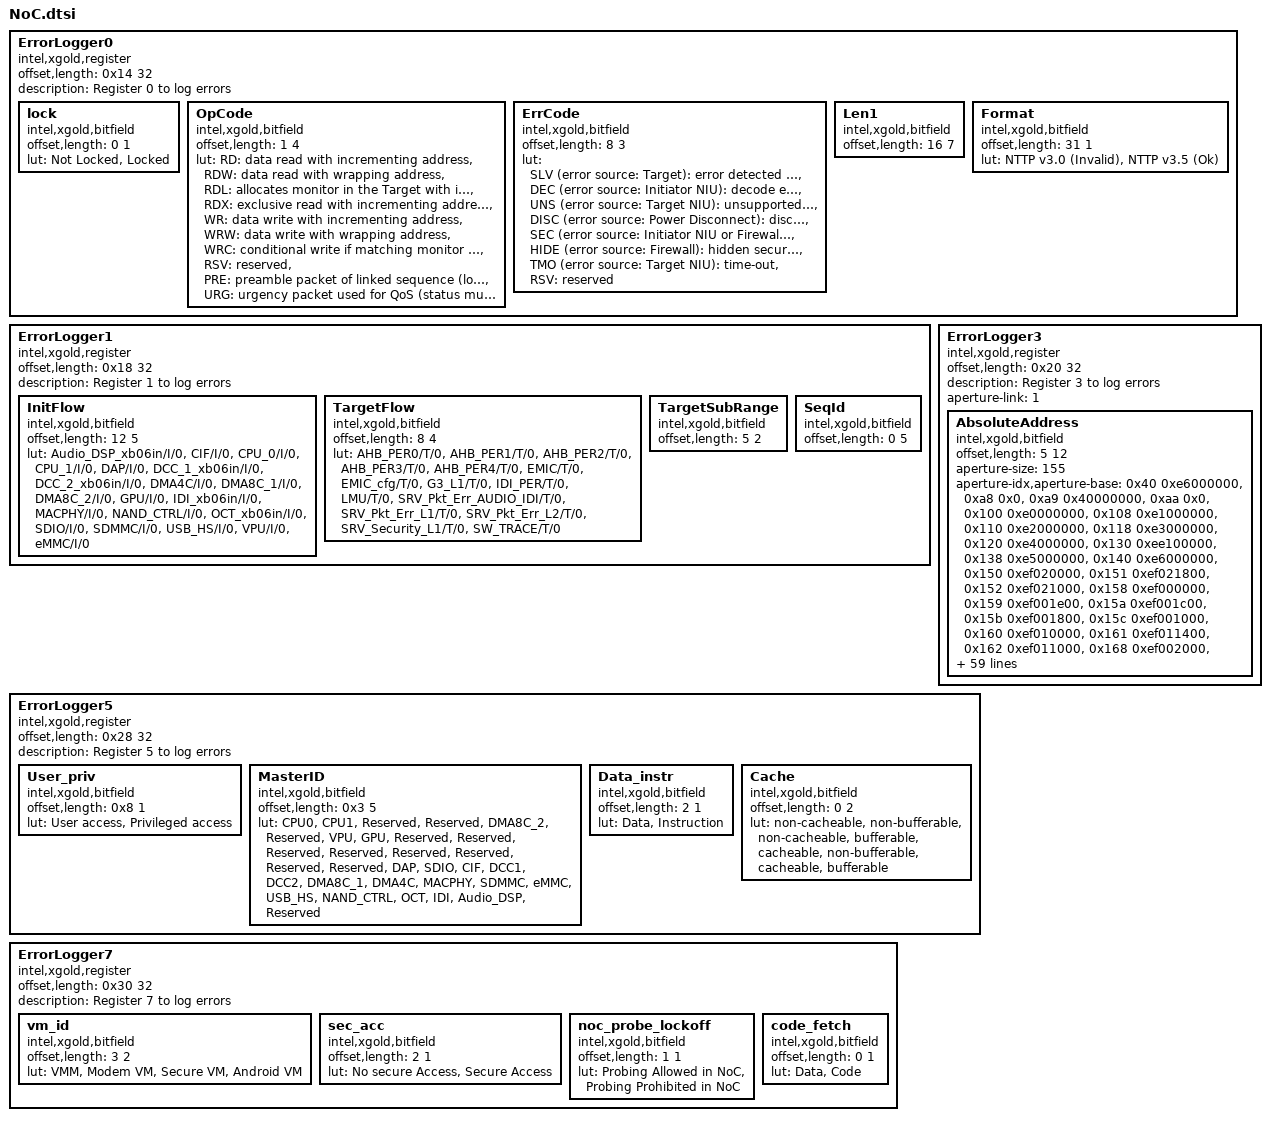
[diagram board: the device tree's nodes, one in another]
ErrorLogger0 {
	compatible = "intel,xgold,register";
	offset,length = < 0x14 32>;
	description = "Register 0 to log errors";
	lock {
		compatible = "intel,xgold,bitfield";
		offset,length = < 0 1>;
		lut = "Not Locked", "Locked";
	};
	OpCode {
		compatible = "intel,xgold,bitfield";
		offset,length = < 1 4>;
		lut = "RD: data read with incrementing address",
			"RDW: data read with wrapping address",
			"RDL: allocates monitor in the Target with incrementing address",
			"RDX: exclusive read with incrementing address",
			"WR: data write with incrementing address",
			"WRW: data write with wrapping address",
			"WRC: conditional write if matching monitor in Target is found",
			"RSV: reserved",
			"PRE: preamble packet of linked sequence (locked sequence)",
			"URG: urgency packet used for QoS (status must be REQ)";
	};
	ErrCode {
		compatible = "intel,xgold,bitfield";
		offset,length = < 8 3 >;
		lut = "SLV (error source: Target): error detected by the Slave without any information or no Error",
			"DEC (error source: Initiator NIU): decode error",
			"UNS (error source: Target NIU): unsupported access type",
			"DISC (error source: Power Disconnect): disconnected Target or NoC domain",
			"SEC (error source: Initiator NIU or Firewall): security error",
			"HIDE (error source: Firewall): hidden security error. Will be reported as OK to the initiator",
			"TMO (error source: Target NIU): time-out",
			"RSV: reserved";

	};
	Len1 {
		compatible = "intel,xgold,bitfield";
		offset,length = < 16 7 >;
	};
	Format {
		compatible = "intel,xgold,bitfield";
		offset,length = < 31 1 >;
		lut = "NTTP v3.0 (Invalid)", "NTTP v3.5 (Ok)";
	};
};

ErrorLogger1 {
	compatible = "intel,xgold,register", "intel,xgold,noc,filter,routeid";
	offset,length = < 0x18 32>;
	description = "Register 1 to log errors";
	InitFlow {
		compatible = "intel,xgold,bitfield";
		offset,length = < 12 5 >;
		lut = "Audio_DSP_xb06in/I/0",
			"CIF/I/0",
			"CPU_0/I/0",
			"CPU_1/I/0",
			"DAP/I/0",
			"DCC_1_xb06in/I/0",
			"DCC_2_xb06in/I/0",
			"DMA4C/I/0",
			"DMA8C_1/I/0",
			"DMA8C_2/I/0",
			"GPU/I/0",
			"IDI_xb06in/I/0",
			"MACPHY/I/0",
			"NAND_CTRL/I/0",
			"OCT_xb06in/I/0",
			"SDIO/I/0",
			"SDMMC/I/0",
			"USB_HS/I/0",
			"VPU/I/0",
			"eMMC/I/0";
	};

	TargetFlow {
		compatible = "intel,xgold,bitfield";
		offset,length = < 8 4 >;
		lut = "AHB_PER0/T/0",
			"AHB_PER1/T/0",
			"AHB_PER2/T/0",
			"AHB_PER3/T/0",
			"AHB_PER4/T/0",
			"EMIC/T/0",
			"EMIC_cfg/T/0",
			"G3_L1/T/0",
			"IDI_PER/T/0",
			"LMU/T/0",
			"SRV_Pkt_Err_AUDIO_IDI/T/0",
			"SRV_Pkt_Err_L1/T/0",
			"SRV_Pkt_Err_L2/T/0",
			"SRV_Security_L1/T/0",
			"SW_TRACE/T/0";
	};

	TargetSubRange {
		compatible = "intel,xgold,bitfield";
		offset,length = < 5 2 >;
	};

	SeqId {
		compatible = "intel,xgold,bitfield";
		offset,length = < 0 5 >;
	};
};

ErrorLogger3 {
	/* This register does not really include a bitfield or its bitfield is 32 bits and it provides an offset address */
	/* To calculate the absolute address, you must use the initflow:targetflow:subrange from ErrorLogger3 register */
	/* And use it as an index in the aperture table. Then you must add the value of this register to the value given */
	/* by the table to get the absolute address. */
	compatible = "intel,xgold,register";
	offset,length = < 0x20 32>;
	description = "Register 3 to log errors";
	aperture-link = <1>; /* link to ErrorLogger1 whose information are required to calculate real absolute address */
	AbsoluteAddress {
		compatible = "intel,xgold,bitfield";
		offset,length = < 5 12 >;				/* bitfield initflow:targeflow:subrange from aperture-link register */
		aperture-size= < 155 >;					/* Number of line in the aperture table below */
		aperture-idx,aperture-base =			/* Aperture_idx is concatenation of initflow:targetflow:subrange bitfield from ErrorLogger1 */
			<0x40	0xe6000000>,
			<0xa8	0x0>,
			<0xa9	0x40000000>,
			<0xaa	0x0>,
			<0x100	0xe0000000>,
			<0x108	0xe1000000>,
			<0x110	0xe2000000>,
			<0x118	0xe3000000>,
			<0x120	0xe4000000>,
			<0x130	0xee100000>,
			<0x138	0xe5000000>,
			<0x140	0xe6000000>,
			<0x150	0xef020000>,
			<0x151	0xef021800>,
			<0x152	0xef021000>,
			<0x158	0xef000000>,
			<0x159	0xef001e00>,
			<0x15a	0xef001c00>,
			<0x15b	0xef001800>,
			<0x15c	0xef001000>,
			<0x160	0xef010000>,
			<0x161	0xef011400>,
			<0x162	0xef011000>,
			<0x168	0xef002000>,
			<0x169	0xef002400>,
			<0x170	0x80000000>,
			<0x1a8	0x0>,
			<0x1a9	0x40000000>,
			<0x1aa	0x0>,
			<0x1c8	0xfff30000>,
			<0x1c9	0xfff20000>,
			<0x1ca	0xfff00000>,
			<0x1cb	0xfffc0000>,
			<0x200	0xe0000000>,
			<0x208	0xe1000000>,
			<0x210	0xe2000000>,
			<0x218	0xe3000000>,
			<0x220	0xe4000000>,
			<0x228	0x0>,
			<0x229	0x40000000>,
			<0x22a	0x0>,
			<0x230	0xee100000>,
			<0x238	0xe5000000>,
			<0x240	0xe6000000>,
			<0x248	0xfff30000>,
			<0x249	0xfff20000>,
			<0x24a	0xfff00000>,
			<0x24b	0xfffc0000>,
			<0x250	0xef020000>,
			<0x251	0xef021800>,
			<0x252	0xef021000>,
			<0x258	0xef000000>,
			<0x259	0xef001e00>,
			<0x25a	0xef001c00>,
			<0x25b	0xef001800>,
			<0x25c	0xef001000>,
			<0x260	0xef010000>,
			<0x261	0xef011400>,
			<0x262	0xef011000>,
			<0x268	0xef002000>,
			<0x269	0xef002400>,
			<0x2a8	0x0>,
			<0x2a9	0x40000000>,
			<0x2aa	0x0>,
			<0x328	0x0>,
			<0x329	0x40000000>,
			<0x32a	0x0>,
			<0x390	0xe2000000>,
			<0x398	0xe3000000>,
			<0x3a8	0x0>,
			<0x3a9	0x40000000>,
			<0x3aa	0x0>,
			<0x3c8	0xfff30000>,
			<0x3c9	0xfff20000>,
			<0x3ca	0xfff00000>,
			<0x3cb	0xfffc0000>,
			<0x408	0xe1000000>,
			<0x410	0xe2000000>,
			<0x428	0x0>,
			<0x429	0x40000000>,
			<0x42a	0x0>,
			<0x448	0xfff30000>,
			<0x449	0xfff20000>,
			<0x44a	0xfff00000>,
			<0x44b	0xfffc0000>,
			<0x488	0xe1000000>,
			<0x490	0xe2000000>,
			<0x498	0xe3000000>,
			<0x4a8	0x0>,
			<0x4a9	0x40000000>,
			<0x4aa	0x0>,
			<0x4b8	0xe5000000>,
			<0x4c8	0xfff30000>,
			<0x4c9	0xfff20000>,
			<0x4ca	0xfff00000>,
			<0x4cb	0xfffc0000>,
			<0x528	0x0>,
			<0x529	0x40000000>,
			<0x52a	0x0>,
			<0x598	0xe3000000>,
			<0x5a8	0x0>,
			<0x5a9	0x40000000>,
			<0x5aa	0x0>,
			<0x5c8	0xfff30000>,
			<0x5c9	0xfff20000>,
			<0x5ca	0xfff00000>,
			<0x5cb	0xfffc0000>,
			<0x628	0x0>,
			<0x629	0x40000000>,
			<0x62a	0x0>,
			<0x648	0xfff30000>,
			<0x649	0xfff20000>,
			<0x64a	0xfff00000>,
			<0x64b	0xfffc0000>,
			<0x6a8	0x0>,
			<0x6a9	0x40000000>,
			<0x6aa	0x0>,
			<0x6c8	0xfff30000>,
			<0x6c9	0xfff20000>,
			<0x6ca	0xfff00000>,
			<0x6cb	0xfffc0000>,
			<0x728	0x0>,
			<0x729	0x40000000>,
			<0x72a	0x0>,
			<0x7a8	0x0>,
			<0x7a9	0x40000000>,
			<0x7aa	0x0>,
			<0x7c8	0xfff30000>,
			<0x7c9	0xfff20000>,
			<0x7ca	0xfff00000>,
			<0x7cb	0xfffc0000>,
			<0x828	0x0>,
			<0x829	0x40000000>,
			<0x82a	0x0>,
			<0x848	0xfff30000>,
			<0x849	0xfff20000>,
			<0x84a	0xfff00000>,
			<0x84b	0xfffc0000>,
			<0x8a8	0x0>,
			<0x8a9	0x40000000>,
			<0x8aa	0x0>,
			<0x8c8	0xfff30000>,
			<0x8c9	0xfff20000>,
			<0x8ca	0xfff00000>,
			<0x8cb	0xfffc0000>,
			<0x928	0x0>,
			<0x929	0x40000000>,
			<0x92a	0x0>,
			<0x9a8	0x0>,
			<0x9a9	0x40000000>,
			<0x9aa	0x0>,
			<0x9c8	0xfff30000>,
			<0x9c9	0xfff20000>,
			<0x9ca	0xfff00000>,
			<0x9cb	0xfffc0000>;
	};
};

ErrorLogger5 {
	compatible = "intel,xgold,register";
	offset,length = < 0x28 32>;
	description = "Register 5 to log errors";

	User_priv {
		compatible = "intel,xgold,bitfield";
		offset,length = < 0x8 1>;
		lut = "User access", "Privileged access";
	};

	MasterID {
		compatible = "intel,xgold,bitfield";
		offset,length = < 0x3 5>;
		lut = "CPU0",
			"CPU1",
			"Reserved",
			"Reserved",
			"DMA8C_2",
			"Reserved",
			"VPU",
			"GPU",
			"Reserved",
			"Reserved",
			"Reserved",
			"Reserved",
			"Reserved",
			"Reserved",
			"Reserved",
			"Reserved",
			"DAP",
			"SDIO",
			"CIF",
			"DCC1",
			"DCC2",
			"DMA8C_1",
			"DMA4C",
			"MACPHY",
			"SDMMC",
			"eMMC",
			"USB_HS",
			"NAND_CTRL",
			"OCT",
			"IDI",
			"Audio_DSP",
			"Reserved";
	};

	Data_instr {
		compatible = "intel,xgold,bitfield";
		offset,length = < 2 1>;
		lut = "Data", "Instruction";
	};

	Cache {
		compatible = "intel,xgold,bitfield";
		offset,length = < 0 2>;
		lut = "non-cacheable, non-bufferable",
			"non-cacheable, bufferable",
			"cacheable, non-bufferable",
			"cacheable, bufferable";
	};
};

ErrorLogger7 {
	compatible = "intel,xgold,register", "intel,xgold,noc,filter,security";
	offset,length = < 0x30 32>;
	description = "Register 7 to log errors";
	vm_id {
		compatible = "intel,xgold,bitfield";
		offset,length = < 3 2>;
		lut = "VMM", "Modem VM", "Secure VM", "Android VM";
	};

	sec_acc {
		compatible = "intel,xgold,bitfield";
		offset,length = < 2 1>;
		lut = "No secure Access", "Secure Access";
	};

	noc_probe_lockoff {
		compatible = "intel,xgold,bitfield";
		offset,length = < 1 1>;
		lut = "Probing Allowed in NoC", "Probing Prohibited in NoC";
	};

	code_fetch {
		compatible = "intel,xgold,bitfield";
		offset,length = < 0 1>;
		lut = "Data", "Code";
	};

};
